# rCSL_dmaxintc_001 register map
Vendor: Texas Instruments
Peripheral module from a debugger description file (folder c674x).
Registers are 32-bit, access not given, reset 0x0 unless marked. A register's access mark holds for its fields unless they carry their own. Offsets are as the file gives them; lines under a group give offsets from that group; [hi:lo] are bit positions; {n}, {i} and the like mark numbered series; 'fields as' and 'values as' point back to an identical list; <NAME> marks a mode.

## dMAXINTC
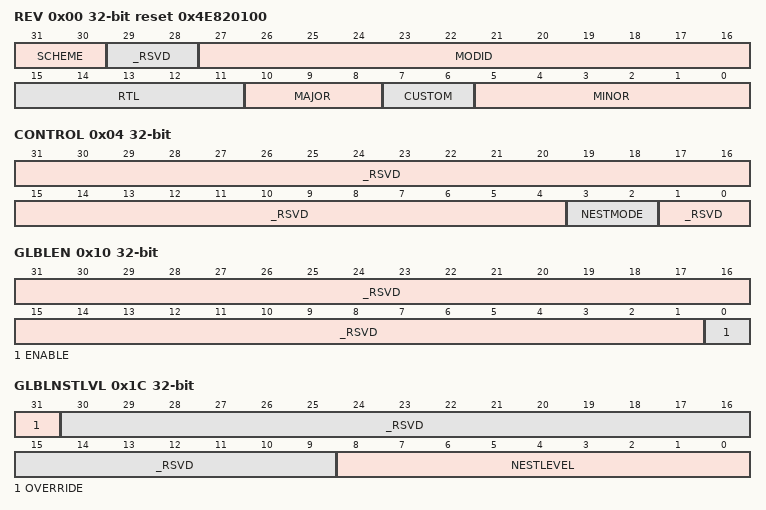
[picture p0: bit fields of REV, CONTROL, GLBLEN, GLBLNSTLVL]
0x00 REV reset 0x4E820100 — Revision Register
  [31:30] SCHEME ro
  [29:28] _RSVD — (access N)
  [27:16] MODID ro — Module ID
  [15:11] RTL ro
  [10:8] MAJOR ro
  [7:6] CUSTOM ro
  [5:0] MINOR ro
0x04 CONTROL
  [31:4] _RSVD — (access N)
  [3:2] NESTMODE rw — Nesting Mode
    0=NONEST; 1=INDIVIDUAL; 2=GLOBAL; 3=MANUAL
  [1:0] _RSVD — (access N)
0x10 GLBLEN — Global Enable Register
  [31:1] _RSVD — (access N)
  [0] ENABLE rw
    0=DISABLE; 1=ENABLE
0x1C GLBLNSTLVL — Global Nesting Level Register
  [31] OVERRIDE wo — Override automatic nesting level
    0=DISABLE; 1=ENABLE
  [30:9] _RSVD — (access N)
  [8:0] NESTLEVEL rw — Current global nesting level
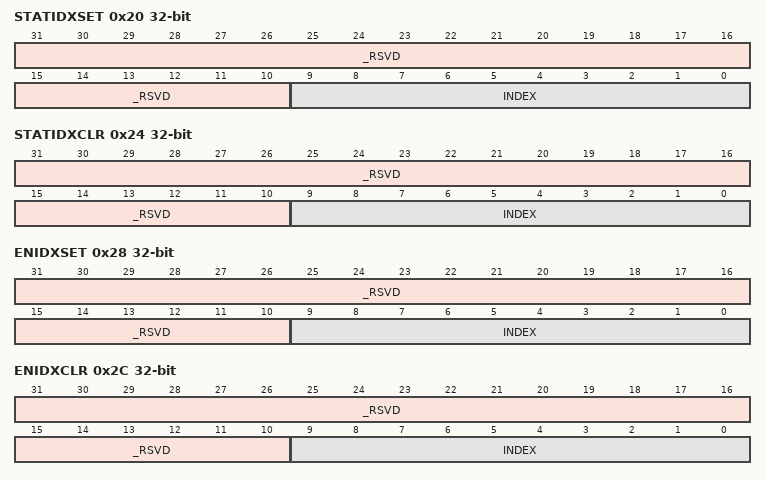
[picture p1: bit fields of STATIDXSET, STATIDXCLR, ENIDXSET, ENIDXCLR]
0x20 STATIDXSET — Status Index Set Register
  [31:10] _RSVD — (access N)
  [9:0] INDEX wo — Set status of interrupt
0x24 STATIDXCLR — Status Index Clear Register
  [31:10] _RSVD — (access N)
  [9:0] INDEX wo — Clear status of interrupt
0x28 ENIDXSET — Enable Index Set Register
  [31:10] _RSVD — (access N)
  [9:0] INDEX wo — Set enable of interrupt
0x2C ENIDXCLR — Enable Index Clear Register
  [31:10] _RSVD — (access N)
  [9:0] INDEX wo — Clear enable of interrupt
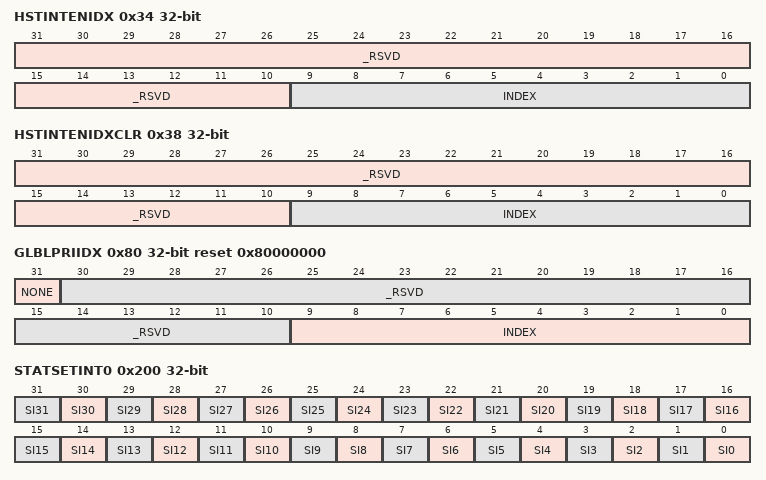
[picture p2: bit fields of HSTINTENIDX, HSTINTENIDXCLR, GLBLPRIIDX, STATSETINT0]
0x34 HSTINTENIDX — Host Interrupt Enable Index Set Register
  [31:10] _RSVD — (access N)
  [9:0] INDEX wo — Set enable of host interrupt
0x38 HSTINTENIDXCLR — Host Interrupt Enable Index Clear Register
  [31:10] _RSVD — (access N)
  [9:0] INDEX wo — Clear enable of host interupt
0x80 GLBLPRIIDX reset 0x80000000 — Global Prioritized Index Register
  [31] NONE ro — No interrupt pending
  [30:10] _RSVD — (access N)
  [9:0] INDEX ro — Highest priority index pending across all interrupts
0x200 STATSETINT0 rw — Status Raw/Set Register 0
  [all] fields
    0=NOEFFECT; 1=SET
  [n] SI{n} (n=0..31) — System Interrupt {n} Raw Status; Write 1 to set
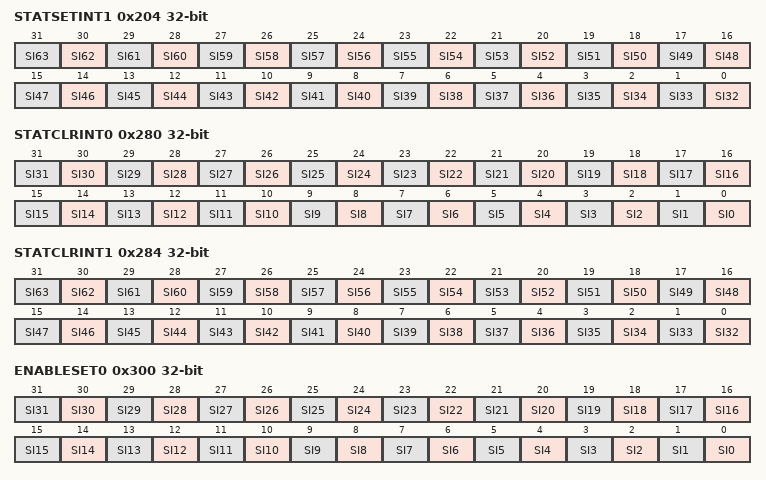
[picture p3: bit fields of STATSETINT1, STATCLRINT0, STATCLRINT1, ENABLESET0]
0x204 STATSETINT1 rw — Status Raw/Set Register 1
  [all] fields
    0=NOEFFECT; 1=SET
  [n-32] SI{n} (n=32..63) — System Interrupt {n} Raw Status; Write 1 to set
0x280 STATCLRINT0 rw — Status Enabled/Clear Register 0
  [all] fields
    0=NOEFFECT; 1=CLEAR
  [n] SI{n} (n=0..31) — System Interrupt {n} Raw Status; Write 1 to clear
0x284 STATCLRINT1 rw — Status Enabled/Clear Register 1
  [all] fields
    0=NOEFFECT; 1=CLEAR
  [n-32] SI{n} (n=32..63) — System Interrupt {n} Raw Status; Write 1 to clear
0x300 ENABLESET0 rw — Enable Set Register 0
  [all] fields
    0=NOEFFECT; 1=SET
  [n] SI{n} (n=0..31) — System Interrupt {n} Enable Set; Write 1 to set
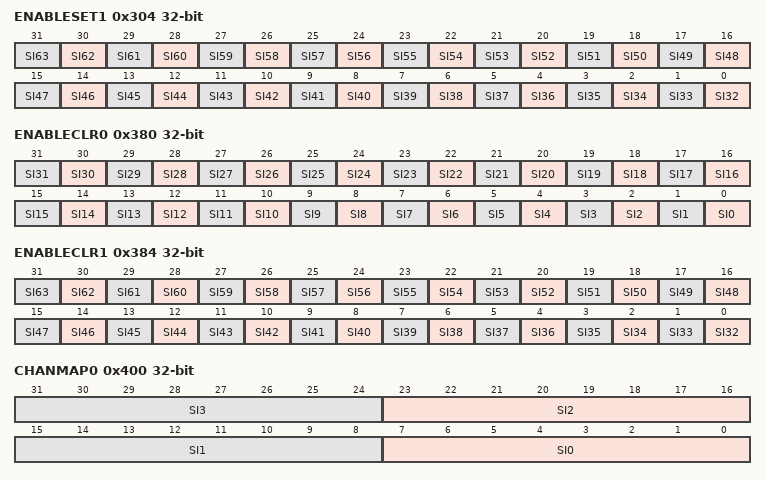
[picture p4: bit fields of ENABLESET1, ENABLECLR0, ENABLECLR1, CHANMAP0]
0x304 ENABLESET1 rw — Enable Set Register 1
  [all] fields
    0=NOEFFECT; 1=SET
  [n-32] SI{n} (n=32..63) — System Interrupt {n} Enable Set; Write 1 to set
0x380 ENABLECLR0 rw — Enable Clear Register 0
  [all] fields
    0=NOEFFECT; 1=CLEAR
  [n] SI{n} (n=0..31) — System Interrupt {n} Enable Clear; Write 1 to clear
0x384 ENABLECLR1 rw — Enable Clear Register 1
  [all] fields
    0=NOEFFECT; 1=CLEAR
  [n-32] SI{n} (n=32..63) — System Interrupt {n} Enable Clear; Write 1 to clear
0x400 CHANMAP0 rw — Channel Map Register 0
  [8n+7:8n] SI{n} (n=0..3) — Channel map for System Interrupt {n}
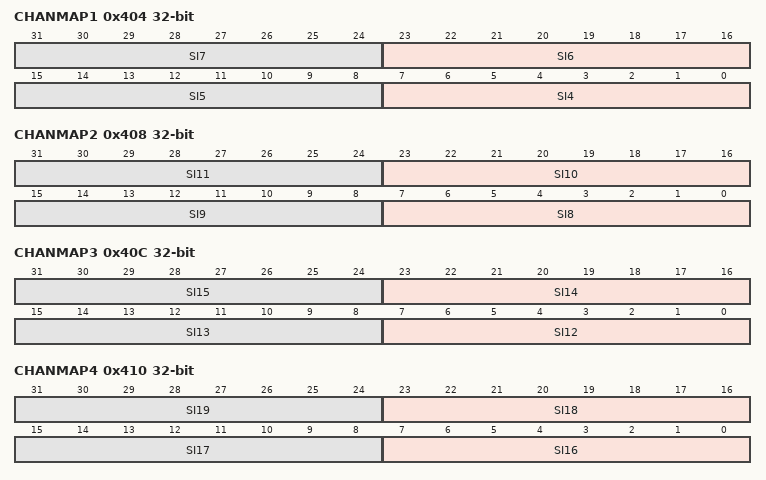
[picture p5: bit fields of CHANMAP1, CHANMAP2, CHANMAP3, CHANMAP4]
0x404 CHANMAP1 rw — Channel Map Register 1
  [8n-25:8n-32] SI{n} (n=4..7) — Channel map for System Interrupt {n}
0x408 CHANMAP2 rw — Channel Map Register 2
  [8n-57:8n-64] SI{n} (n=8..11) — Channel map for System Interrupt {n}
0x40C CHANMAP3 rw — Channel Map Register 3
  [8n-89:8n-96] SI{n} (n=12..15) — Channel map for System Interrupt {n}
0x410 CHANMAP4 rw — Channel Map Register 4
  [8n-121:8n-128] SI{n} (n=16..19) — Channel map for System Interrupt {n}
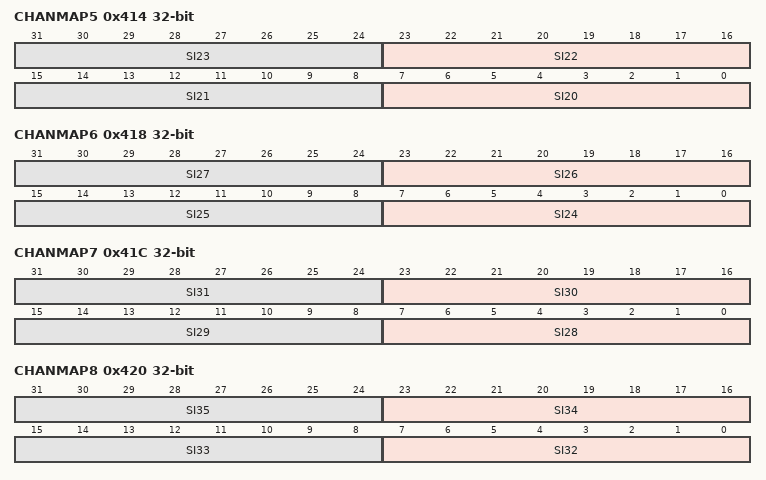
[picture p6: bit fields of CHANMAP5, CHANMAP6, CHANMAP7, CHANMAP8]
0x414 CHANMAP5 rw — Channel Map Register 5
  [8n-153:8n-160] SI{n} (n=20..23) — Channel map for System Interrupt {n}
0x418 CHANMAP6 rw — Channel Map Register 6
  [8n-185:8n-192] SI{n} (n=24..27) — Channel map for System Interrupt {n}
0x41C CHANMAP7 rw — Channel Map Register 7
  [8n-217:8n-224] SI{n} (n=28..31) — Channel map for System Interrupt {n}
0x420 CHANMAP8 rw — Channel Map Register 8
  [8n-249:8n-256] SI{n} (n=32..35) — Channel map for System Interrupt {n}
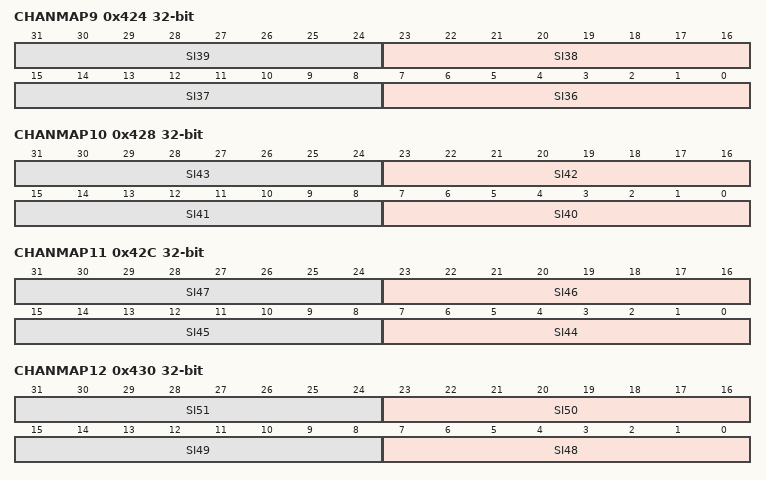
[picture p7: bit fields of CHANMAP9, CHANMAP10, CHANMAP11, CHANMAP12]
0x424 CHANMAP9 rw — Channel Map Register 9
  [8n-281:8n-288] SI{n} (n=36..39) — Channel map for System Interrupt {n}
0x428 CHANMAP10 rw — Channel Map Register 10
  [8n-313:8n-320] SI{n} (n=40..43) — Channel map for System Interrupt {n}
0x42C CHANMAP11 rw — Channel Map Register 11
  [8n-345:8n-352] SI{n} (n=44..47) — Channel map for System Interrupt {n}
0x430 CHANMAP12 rw — Channel Map Register 12
  [8n-377:8n-384] SI{n} (n=48..51) — Channel map for System Interrupt {n}
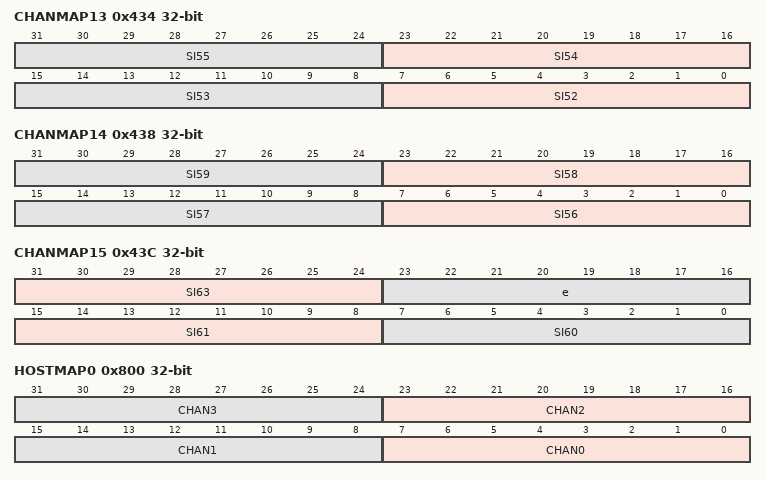
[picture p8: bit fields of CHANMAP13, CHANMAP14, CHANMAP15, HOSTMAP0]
0x434 CHANMAP13 rw — Channel Map Register 13
  [8n-409:8n-416] SI{n} (n=52..55) — Channel map for System Interrupt {n}
0x438 CHANMAP14 rw — Channel Map Register 14
  [8n-441:8n-448] SI{n} (n=56..59) — Channel map for System Interrupt {n}
0x43C CHANMAP15 rw — Channel Map Register 15
  [31:24] SI63 — Channel map for System Interrupt 63
  [23:16] e — Channel map for System Interrupt 62
  [15:8] SI61 — Channel map for System Interrupt 61
  [7:0] SI60 — Channel map for System Interrupt 60
0x800 HOSTMAP0 rw — Host Interrupt Map Register 0
  [8n+7:8n] CHAN{n} (n=0..3) — Host Interrupt map for Channel {n}
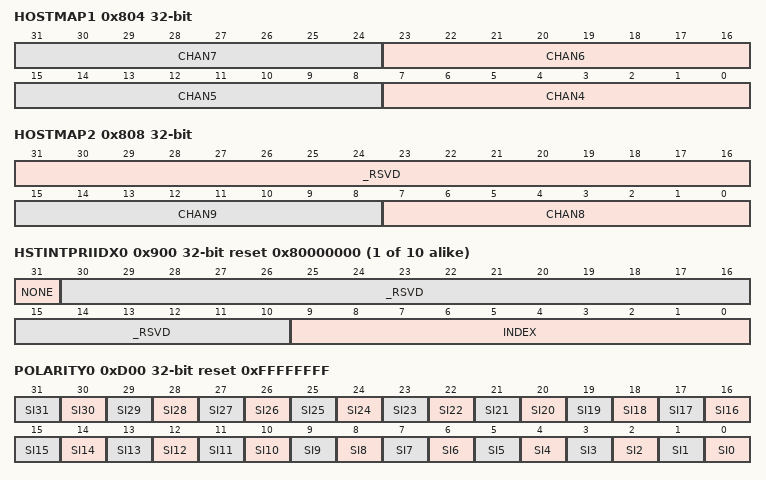
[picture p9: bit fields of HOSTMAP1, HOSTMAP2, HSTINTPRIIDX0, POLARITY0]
0x804 HOSTMAP1 rw — Host Interrupt Map Register 1
  [8n-25:8n-32] CHAN{n} (n=4..7) — Host Interrupt map for Channel {n}
0x808 HOSTMAP2 — Host Interrupt Map Register 2
  [31:16] _RSVD — (access N)
  [15:8] CHAN9 rw — Host Interrupt map for Channel 9
  [7:0] CHAN8 rw — Host Interrupt map for Channel 8
{0x900+4i} HSTINTPRIIDX{i} reset 0x80000000 (i=0..9) — Host Interrupt Prioritized Index Register {i}
  [31] NONE ro — No pending interrupt
  [30:10] _RSVD — (access N)
  [9:0] INDEX ro — Interrupt number of the highest priority pending interrupt for Host Interrupt {i}
0xD00 POLARITY0 rw reset 0xFFFFFFFF — System Interrupt Polarity Register 0
  [all] fields
    0=LOW; 1=HIGH
  [n] SI{n} (n=0..31) — System Interrupt {n} polarity; 0=LOW, 1=HIGH
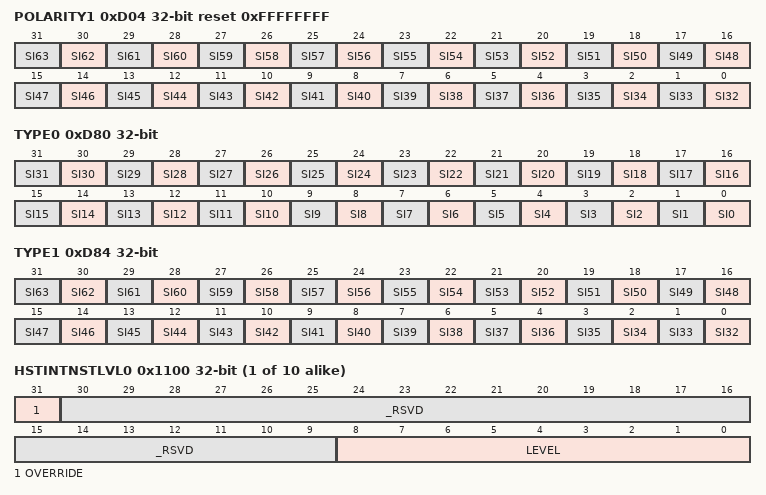
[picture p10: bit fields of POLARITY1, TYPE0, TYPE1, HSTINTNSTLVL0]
0xD04 POLARITY1 rw reset 0xFFFFFFFF — System Interrupt Polarity Register 1
  [all] fields
    0=LOW; 1=HIGH
  [n-32] SI{n} (n=32..63) — System Interrupt {n} polarity; 0=LOW, 1=HIGH
0xD80 TYPE0 rw — System Interrupt Type Register 0
  [all] fields
    0=LEVEL; 0=PULSE; 1=EDGE
  [n] SI{n} (n=0..31) — System Interrupt {n} type; 0=LEVEL or PULSE, 1=EDGE
0xD84 TYPE1 rw — System Interrupt Type Register 1
  [all] fields
    0=LEVEL; 0=PULSE; 1=EDGE
  [n-32] SI{n} (n=32..63) — System Interrupt {n} type; 0=LEVEL or PULSE, 1=EDGE
{0x1100+4i} HSTINTNSTLVL{i} (i=0..9) — Host Interrupt Nesting Level Register {i}
  [31] OVERRIDE wo — Override auto updating of the nesting level and use LEVEL
    0=DISABLE; 1=ENABLE
  [30:9] _RSVD — (access N)
  [8:0] LEVEL rw — Current nesting level for the Host Interrupt {i}
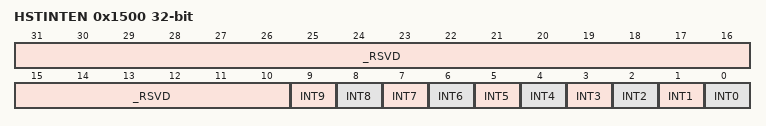
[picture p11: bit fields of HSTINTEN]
0x1500 HSTINTEN — Host Interrupt Enable Register
  [31:10] _RSVD — (access N)
  [n] INT{n} rw (n=0..9) — Enable Host Interrupt {n}
    0=DISABLE; 1=ENABLE
